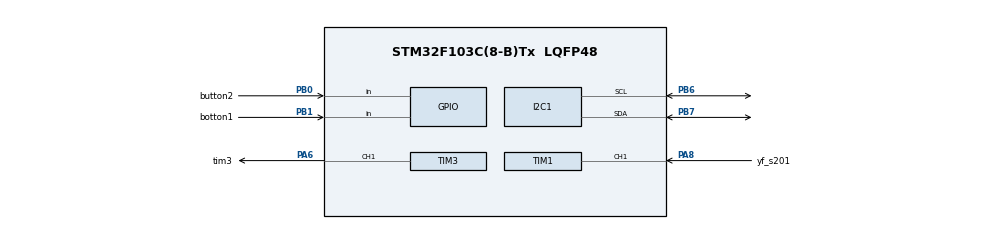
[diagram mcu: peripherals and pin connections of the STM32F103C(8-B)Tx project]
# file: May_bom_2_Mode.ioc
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Mcu.Family=STM32F1
Mcu.Name=STM32F103C(8-B)Tx
Mcu.Package=LQFP48
NVIC.PriorityGroup=NVIC_PRIORITYGROUP_4
NVIC.TIM1_CC_IRQn=true\:0\:0\:false\:false\:true\:true\:true\:true
NVIC.TIM3_IRQn=true\:0\:0\:false\:false\:true\:true\:true\:true
PA13.Mode=Serial_Wire
PA13.Signal=SYS_JTMS-SWDIO
PA14.Mode=Serial_Wire
PA14.Signal=SYS_JTCK-SWCLK
PA6.GPIO_Label=tim3
PA6.Signal=S_TIM3_CH1
PA8.GPIO_Label=yf_s201
PA8.Signal=S_TIM1_CH1
PB0.GPIO_Label=button2
PB0.Signal=GPIO_Input
PB1.GPIO_Label=botton1
PB1.GPIO_PuPd=GPIO_PULLUP
PB1.Signal=GPIO_Input
PB6.Mode=I2C
PB6.Signal=I2C1_SCL
PB7.Mode=I2C
PB7.Signal=I2C1_SDA
ProjectManager.HeapSize=0x200
ProjectManager.StackSize=0x400
ProjectManager.TargetToolchain=STM32CubeIDE
RCC.APB1Freq_Value=8000000
RCC.APB2Freq_Value=8000000
SH.S_TIM1_CH1.0=TIM1_CH1,Input_Capture1_from_TI1
SH.S_TIM3_CH1.0=TIM3_CH1,PWM Generation1 CH1
TIM1.Channel-Input_Capture1_from_TI1=TIM_CHANNEL_1
TIM3.Channel-PWM\ Generation1\ CH1=TIM_CHANNEL_1
TIM3.Period=999
TIM3.Prescaler=71
board=custom

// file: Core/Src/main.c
#include "main.h"
#include <stdio.h>
#include "I2C_LCD.h"

I2C_HandleTypeDef hi2c1;

TIM_HandleTypeDef htim1;
TIM_HandleTypeDef htim3;

/* USER CODE BEGIN PV */
volatile uint32_t count_xung = 0;
volatile float luong_nuoc = 0.0;
volatile uint32_t capture_goc = 0;
volatile float tong_luong_nuoc = 0.0;
/* USER CODE END PV */
void HAL_TIM_IC_CaptureCallback(TIM_HandleTypeDef *htim)
{
    if (htim->Channel == HAL_TIM_ACTIVE_CHANNEL_1)
    {
        uint32_t capture_value = HAL_TIM_ReadCapturedValue(htim, TIM_CHANNEL_1);

        // Tính toán thời gian giữa hai lần capture
        uint32_t time_between_capture = capture_value - capture_goc;
        capture_goc = capture_value;

        // Tính toán tần số xung
        float so_xung_thu_duoc = 1000000.0f / time_between_capture; // Tính bằng tần số 1 MHz (1 micro giây)

        // Mỗi xung tương ứng với L
        luong_nuoc = (so_xung_thu_duoc * 0.1f) / 7.5f; // L/s
    }
}
void SystemClock_Config(void);
static void MX_GPIO_Init(void);
static void MX_I2C1_Init(void);
static void MX_TIM1_Init(void);
static void MX_TIM3_Init(void);

int main(void)
{

  /* Reset of all peripherals, Initializes the Flash interface and the Systick. */
  HAL_Init();

  /* Configure the system clock */
  SystemClock_Config();

  /* Initialize all configured peripherals */
  MX_GPIO_Init();
  MX_I2C1_Init();
  MX_TIM1_Init();
  MX_TIM3_Init();
  /* USER CODE BEGIN 2 */
HAL_TIM_Base_Start(&htim1);
HAL_TIM_Base_Start(&htim3);
HAL_TIM_IC_Start_IT(&htim1, TIM_CHANNEL_1);
HAL_TIM_PWM_Start(&htim3, TIM_CHANNEL_1); // Khởi động PWM
  /* USER CODE END 2 */
   LCD_Init();
   LCD_SendString("Flow Monitor");
   HAL_Delay(3000);
   LCD_Clear();
   char message[64];
  /* Infinite loop */
  while (1)
  {
	  tong_luong_nuoc = (float)luong_nuoc;
	         LCD_PutCursor(0, 0);
	         sprintf(message, " %.2f L/s", tong_luong_nuoc);
	         LCD_SendString("Flow: ");
	         LCD_PutCursor(1, 0);
	         LCD_SendString(message);

	         if (HAL_GPIO_ReadPin(botton1_GPIO_Port, botton1_Pin) == GPIO_PIN_RESET)
	         {
	             __HAL_TIM_SET_COMPARE(&htim3, TIM_CHANNEL_1, 700); // Bơm nhanh (70% PWM)
	         }

	         if (HAL_GPIO_ReadPin(button2_GPIO_Port, button2_Pin) == GPIO_PIN_RESET)
	         {
	             __HAL_TIM_SET_COMPARE(&htim3, TIM_CHANNEL_1, 300); // Bơm chậm (30% PWM)
	         }

	         HAL_Delay(1000);
  }
}

void SystemClock_Config(void)
{
  RCC_OscInitTypeDef RCC_OscInitStruct = {0};
  RCC_ClkInitTypeDef RCC_ClkInitStruct = {0};

  /** Initializes the RCC Oscillators according to the specified parameters
  * in the RCC_OscInitTypeDef structure.
  */
  RCC_OscInitStruct.OscillatorType = RCC_OSCILLATORTYPE_HSI;
  RCC_OscInitStruct.HSIState = RCC_HSI_ON;
  RCC_OscInitStruct.HSICalibrationValue = RCC_HSICALIBRATION_DEFAULT;
  RCC_OscInitStruct.PLL.PLLState = RCC_PLL_NONE;
  if (HAL_RCC_OscConfig(&RCC_OscInitStruct) != HAL_OK)
  {
    Error_Handler();
  }

  /** Initializes the CPU, AHB and APB buses clocks
  */
  RCC_ClkInitStruct.ClockType = RCC_CLOCKTYPE_HCLK|RCC_CLOCKTYPE_SYSCLK
                              |RCC_CLOCKTYPE_PCLK1|RCC_CLOCKTYPE_PCLK2;
  RCC_ClkInitStruct.SYSCLKSource = RCC_SYSCLKSOURCE_HSI;
  RCC_ClkInitStruct.AHBCLKDivider = RCC_SYSCLK_DIV1;
  RCC_ClkInitStruct.APB1CLKDivider = RCC_HCLK_DIV1;
  RCC_ClkInitStruct.APB2CLKDivider = RCC_HCLK_DIV1;

  if (HAL_RCC_ClockConfig(&RCC_ClkInitStruct, FLASH_LATENCY_0) != HAL_OK)
  {
    Error_Handler();
  }
}

static void MX_I2C1_Init(void)
{

  hi2c1.Instance = I2C1;
  hi2c1.Init.ClockSpeed = 100000;
  hi2c1.Init.DutyCycle = I2C_DUTYCYCLE_2;
  hi2c1.Init.OwnAddress1 = 0;
  hi2c1.Init.AddressingMode = I2C_ADDRESSINGMODE_7BIT;
  hi2c1.Init.DualAddressMode = I2C_DUALADDRESS_DISABLE;
  hi2c1.Init.OwnAddress2 = 0;
  hi2c1.Init.GeneralCallMode = I2C_GENERALCALL_DISABLE;
  hi2c1.Init.NoStretchMode = I2C_NOSTRETCH_DISABLE;
  if (HAL_I2C_Init(&hi2c1) != HAL_OK)
  {
    Error_Handler();
  }

}

static void MX_TIM1_Init(void)
{

  TIM_MasterConfigTypeDef sMasterConfig = {0};
  TIM_IC_InitTypeDef sConfigIC = {0};

  htim1.Instance = TIM1;
  htim1.Init.Prescaler = 0;
  htim1.Init.CounterMode = TIM_COUNTERMODE_UP;
  htim1.Init.Period = 65535;
  htim1.Init.ClockDivision = TIM_CLOCKDIVISION_DIV1;
  htim1.Init.RepetitionCounter = 0;
  htim1.Init.AutoReloadPreload = TIM_AUTORELOAD_PRELOAD_DISABLE;
  if (HAL_TIM_IC_Init(&htim1) != HAL_OK)
  {
    Error_Handler();
  }
  sMasterConfig.MasterOutputTrigger = TIM_TRGO_RESET;
  sMasterConfig.MasterSlaveMode = TIM_MASTERSLAVEMODE_DISABLE;
  if (HAL_TIMEx_MasterConfigSynchronization(&htim1, &sMasterConfig) != HAL_OK)
  {
    Error_Handler();
  }
  sConfigIC.ICPolarity = TIM_INPUTCHANNELPOLARITY_RISING;
  sConfigIC.ICSelection = TIM_ICSELECTION_DIRECTTI;
  sConfigIC.ICPrescaler = TIM_ICPSC_DIV1;
  sConfigIC.ICFilter = 0;
  if (HAL_TIM_IC_ConfigChannel(&htim1, &sConfigIC, TIM_CHANNEL_1) != HAL_OK)
  {
    Error_Handler();
  }

}

static void MX_TIM3_Init(void)
{

  TIM_MasterConfigTypeDef sMasterConfig = {0};
  TIM_OC_InitTypeDef sConfigOC = {0};

  htim3.Instance = TIM3;
  htim3.Init.Prescaler = 71;
  htim3.Init.CounterMode = TIM_COUNTERMODE_UP;
  htim3.Init.Period = 999;
  htim3.Init.ClockDivision = TIM_CLOCKDIVISION_DIV1;
  htim3.Init.AutoReloadPreload = TIM_AUTORELOAD_PRELOAD_DISABLE;
  if (HAL_TIM_PWM_Init(&htim3) != HAL_OK)
  {
    Error_Handler();
  }
  sMasterConfig.MasterOutputTrigger = TIM_TRGO_RESET;
  sMasterConfig.MasterSlaveMode = TIM_MASTERSLAVEMODE_DISABLE;
  if (HAL_TIMEx_MasterConfigSynchronization(&htim3, &sMasterConfig) != HAL_OK)
  {
    Error_Handler();
  }
  sConfigOC.OCMode = TIM_OCMODE_PWM1;
  sConfigOC.Pulse = 0;
  sConfigOC.OCPolarity = TIM_OCPOLARITY_HIGH;
  sConfigOC.OCFastMode = TIM_OCFAST_DISABLE;
  if (HAL_TIM_PWM_ConfigChannel(&htim3, &sConfigOC, TIM_CHANNEL_1) != HAL_OK)
  {
    Error_Handler();
  }
  HAL_TIM_MspPostInit(&htim3);

}

static void MX_GPIO_Init(void)
{
  GPIO_InitTypeDef GPIO_InitStruct = {0};

  /* GPIO Ports Clock Enable */
  __HAL_RCC_GPIOA_CLK_ENABLE();
  __HAL_RCC_GPIOB_CLK_ENABLE();

  /*Configure GPIO pins : botton1_Pin button2_Pin */
  GPIO_InitStruct.Pin = botton1_Pin|button2_Pin;
  GPIO_InitStruct.Mode = GPIO_MODE_INPUT;
  GPIO_InitStruct.Pull = GPIO_PULLUP;
  HAL_GPIO_Init(GPIOB, &GPIO_InitStruct);

}

void Error_Handler(void)
{
  __disable_irq();
  while (1)
  {
  }
}
